# ODS5010 register map
Vendor: OCS; Series: ODS5010; File version: 1.0
CPU: CM0plus r0p0, little endian, MPU, FPU, 4 interrupt priority bits
Registers are 32-bit, read-write, reset 0x0 unless marked. A register's access mark holds for its fields unless they carry their own. Offsets are from the block's base; [hi:lo] are bit positions.

## IWDG — Independent Watchdog Timer
Base 0x40003000; register names take the prefix IWDG_
0x00 RLR — Reload Register
  [31:0] RLR — Reload value
0x04 CNTR — Counter Register
  [31:0] CNTR — Counter value
0x08 CR — Control Register
  [31:0] CR — Control bits
0x0C KR — Key Register
  [31:0] KR — Key value
0x10 SR — Status Register
  [31:0] SR — Status bits

## HALL — Hall Sensor
Base 0x40006400; register names take the prefix HALL_
0x00 VERID — Version ID Register
  [31:0] VERID — Version ID
0x04 IR — Hall Sensor Interrupt Status Register
  [31:0] IR — Interrupt Status
0x08 IE — Hall Sensor Interrupt Enable Register
  [31:0] IE — Interrupt Enable
0x0C CR — Hall Sensor Control Register
  [31:0] CR — Control Register
0x10 TH — Hall Sensor Threshold Register
  [31:0] TH — Threshold
0x14 CNT — Hall Sensor Counter Register
  [31:0] CNT — Counter
0x18 CCR — Hall Sensor Capture Compare Register
  [31:0] CCR — Capture Compare
0x1C INFO — Hall Sensor Information Register
  [31:0] INFO — Information
0x20 LOCK — Hall Sensor Lock Register

## QEP — Quadrature Encoder Pulse
Base 0x40006430; register names take the prefix QEP_
0x00 CFG — Encoder configuration register
  [31:0] CFG — Encoder configuration
0x04 TH — Encoder count threshold register
  [31:0] TH — Encoder count threshold
0x08 CNT — Encoder count value register
  [31:0] CNT — Encoder count value
0x0C IE — Encoder interrupt enable
0x10 IF — Encoder interrupt flag register
  [31:0] IF — Encoder interrupt flag

## HWMATH — Hardware Mathematical Module, including square root, division, sine and cosine operation functions with status flags
Base 0x40006000; register names take the prefix HWMATH_
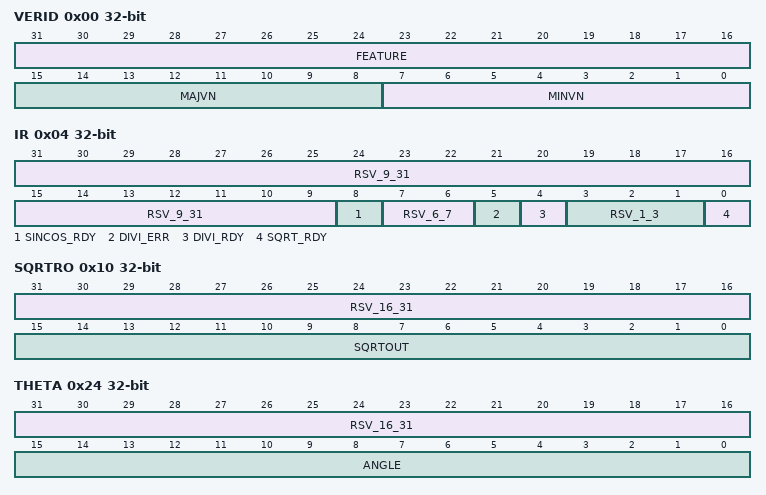
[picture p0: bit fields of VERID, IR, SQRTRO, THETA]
0x00 VERID — Version Identification Register, stores module version and feature information
  [31:16] FEATURE — Feature Identification Bit, indicates the operation functions supported by the module
  [15:8] MAJVN — Major Version Number
  [7:0] MINVN — Minor Version Number
0x04 IR — Interrupt Request Register, contains operation status flags and reserved bits
  [31:9] RSV_9_31 — Reserved Bits, no actual function
  [8] SINCOS_RDY — Sine/Cosine Operation Ready Flag, 1 indicates operation completed
  [7:6] RSV_6_7 — Reserved Bits, no actual function
  [5] DIVI_ERR — Division Operation Error Flag, 1 indicates division by zero or other errors
  [4] DIVI_RDY — Division Operation Ready Flag, 1 indicates operation completed
  [3:1] RSV_1_3 — Reserved Bits, no actual function
  [0] SQRT_RDY — Square Root Operation Ready Flag, 1 indicates operation completed
0x08 IE — Interrupt Enable Register (Reserved Bits)
  [31:0] RSV — Reserved Bits, no actual function
0x0C SQRTRI — Square Root Operation Input Register, stores 32-bit data to be square-rooted
  [31:0] SQRTIN — Square Root Input Data
0x10 SQRTRO — Square Root Operation Result Output Register
  [31:16] RSV_16_31 — Reserved Bits
  [15:0] SQRTOUT — Square Root Operation Result (16-bit valid data)
0x14 DIVIDE — Division Operation Dividend Register
  [31:0] DIVIDE — Division Operation Dividend
0x18 DIVIDS — Division Operation Divisor Register
  [31:0] DIVIDS — Division Operation Divisor
0x1C QUOTI — Division Operation Quotient Register
  [31:0] QUOTI — Division Operation Quotient Result
0x20 REMAIN — Division Operation Remainder Register
  [31:0] REMAIN — Division Operation Remainder Result
0x24 THETA — Sine/Cosine Operation Angle Input Register
  [31:16] RSV_16_31 — Reserved Bits
  [15:0] ANGLE — Input Angle Value (16-bit valid data)
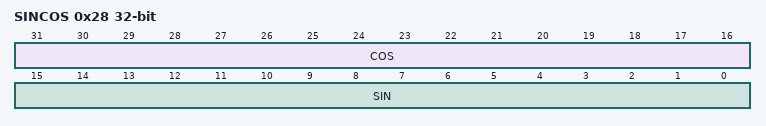
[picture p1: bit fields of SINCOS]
0x28 SINCOS — Sine/Cosine Operation Result Output Register
  [31:16] COS — Cosine Operation Result (16-bit valid data)
  [15:0] SIN — Sine Operation Result (16-bit valid data)
